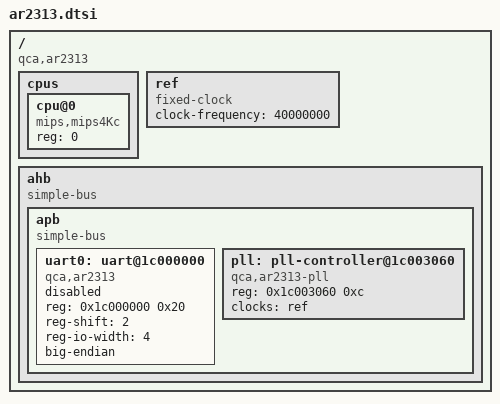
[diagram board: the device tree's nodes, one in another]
/ {
	compatible = "qca,ar2313";

	#address-cells = <1>;
	#size-cells = <1>;

	cpus {
		#address-cells = <1>;
		#size-cells = <0>;

		cpu@0 {
			device_type = "cpu";
			compatible = "mips,mips4Kc";
			reg = <0>;
		};
	};

	ref: ref {
		compatible = "fixed-clock";
		#clock-cells = <0>;
		/* 40 MHz sourced from base band controller */
		clock-frequency = <40000000>;
	};

	ahb {
		compatible = "simple-bus";
		ranges;

		#address-cells = <1>;
		#size-cells = <1>;

		apb {
			compatible = "simple-bus";
			ranges;

			#address-cells = <1>;
			#size-cells = <1>;

			uart0: uart@1c000000 {
				compatible = "qca,ar2313", "ns16550a";
				reg = <0x1c000000 0x20>;

				reg-shift = <2>;
				reg-io-width = <4>;
				big-endian;

				status = "disabled";
			};

			pll: pll-controller@1c003060 {
				compatible = "qca,ar2313-pll", "qca,ar231x-pll";
				reg = <0x1c003060 0xc>;

				clocks = <&ref>;
				clock-names = "ref";

				#clock-cells = <1>;
			};
		};

	};
};
